# ATtiny44 device description
Architecture: AVR8; Family: tinyAVR
Programming and debug interfaces: ISP, HVSP, debugWIRE
Registers are 8-bit, access not given, no defined reset value unless marked. A register's access mark holds for its fields unless they carry their own. Offsets are from the block's base; lines under a group give offsets from that group; [hi:lo] are bit positions; {n}, {i} and the like mark numbered series; 'fields as' and 'values as' point back to an identical list; <NAME> marks a mode.

## Ordering variants
ATtiny44V-10SSU, ATtiny44V-10SSUR: SOIC14, up to 10 MHz, -40 to 85 C, 1.8 to 5.5 V
ATtiny44V-10MU, ATtiny44V-10MUR: QFN20, up to 10 MHz, -40 to 85 C, 1.8 to 5.5 V
ATtiny44-20SSU, ATtiny44-20SSUR: SOIC14, up to 20 MHz, -40 to 85 C, 2.7 to 5.5 V
ATtiny44-20MU, ATtiny44-20MUR: QFN20, up to 20 MHz, -40 to 85 C, 2.7 to 5.5 V
ATtiny44-15SSZ: SOIC14, up to 16 MHz, -40 to 125 C, 2.7 to 5.5 V
ATtiny44-15MZ: QFN20, up to 16 MHz, -40 to 125 C, 2.7 to 5.5 V

## Memory
prog space: start 0x0000 size 0x1000, little endian
  0x0000 FLASH size 0x1000 flash, rw, executable, page 0x40
signatures space: start 0 size 3, little endian
  0 SIGNATURES size 3 signatures, ro
fuses space: start 0 size 0x0003, little endian
  0 FUSES size 0x0003 fuses, rw
lockbits space: start 0 size 0x0001, little endian
  0 LOCKBITS size 0x0001 lockbits, rw
data space: start 0x0000 size 0x0160, little endian
  0x0000 REGISTERS size 0x0020 regs
  0x0020 MAPPED_IO size 0x0040 io
  0x0060 IRAM size 0x0100 ram
eeprom space: start 0x0000 size 0x0100, little endian
  0x0000 EEPROM size 0x0100 eeprom, rw, page 0x04
io space: start 0x00 size 0x40, little endian
osccal space: start 0 size 1, little endian
  0 OSCCAL size 1 osccal, ro

## Peripheral instances (address, pins/pin function, parameters)
PORTA at 0x00 — I/O Port
PORTB at 0x00 — I/O Port
AC at 0x00 — Analog Comparator
ADC at 0x00 — Analog-to-Digital Converter
USI at 0x00 — Universal Serial Interface
EXINT at 0x00 — External Interrupts
EEPROM at 0x00
WDT at 0x00 — Watchdog Timer
TC0 at 0x00 — Timer/Counter, 8-bit
TC1 at 0x00 — Timer/Counter, 16-bit
BOOT_LOAD at 0x00 — Bootloader
CPU at 0x00 — CPU Registers
  parameters: CORE_VERSION=V2, NEW_INSTRUCTIONS=lpm rd,z+
FUSE at 0 in fuses — Fuses
LOCKBIT at 0 in lockbits — Lockbits

## Interrupts
0 RESET — External Pin, Power-on Reset, Brown-out Reset,Watchdog Reset
1 EXT_INT0 — External Interrupt Request 0
2 PCINT0 — Pin Change Interrupt Request 0
3 PCINT1 — Pin Change Interrupt Request 1
4 WDT — Watchdog Time-out
5 TIM1_CAPT — Timer/Counter1 Capture Event
6 TIM1_COMPA — Timer/Counter1 Compare Match A
7 TIM1_COMPB — Timer/Counter1 Compare Match B
8 TIM1_OVF — Timer/Counter1 Overflow
9 TIM0_COMPA — Timer/Counter0 Compare Match A
10 TIM0_COMPB — Timer/Counter0 Compare Match B
11 TIM0_OVF — Timer/Counter0 Overflow
12 ANA_COMP — Analog Comparator
13 ADC — ADC Conversion Complete
14 EE_RDY — EEPROM Ready
15 USI_STR — USI START
16 USI_OVF — USI Overflow

## Properties
SIGNATURES: JTAGID=0x9207, SIGNATURE0=0x1e, SIGNATURE1=0x92, SIGNATURE2=0x07
OCD: OCD_REVISION=1, OCD_DATAREG=0x27, PROGBASE=0x0000

## LOCKBIT — Lockbits
Instances: LOCKBIT 0 in lockbits
0x00 LOCKBIT reset 0xFF
  [1:0] LB — Memory Lock
    0=PROG_VER_DISABLED (Further programming and verification disabled); 2=PROG_DISABLED (Further programming disabled); 3=NO_LOCK (No memory lock features enabled)

## PORTA — I/O Port
Instances: PORTA 0x00
0x39 PINA — Port A Input Pins
0x3A DDRA — Port A Data Direction Register
0x3B PORTA — Port A Data Register

## PORTB — I/O Port
Instances: PORTB 0x00
0x36 PINB bits used 3:0 — Input Pins, Port B
0x37 DDRB bits used 3:0 — Data Direction Register, Port B
0x38 PORTB bits used 3:0 — Data Register, Port B

## AC — Analog Comparator
Instances: AC 0x00
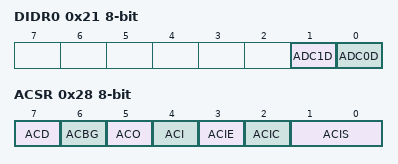
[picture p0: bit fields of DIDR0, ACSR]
0x21 DIDR0
  [1] ADC1D — ADC 1 Digital input buffer disable
  [0] ADC0D — ADC 0 Digital input buffer disable
0x23 ADCSRB — ADC Control and Status Register B
  [6] ACME — Analog Comparator Multiplexer Enable
0x28 ACSR — Analog Comparator Control And Status Register
  [7] ACD — Analog Comparator Disable
  [6] ACBG — Analog Comparator Bandgap Select
  [5] ACO — Analog Compare Output
  [4] ACI — Analog Comparator Interrupt Flag
  [3] ACIE — Analog Comparator Interrupt Enable
  [2] ACIC — Analog Comparator Input Capture Enable
  [1:0] ACIS — Analog Comparator Interrupt Mode Select bits
    0=INTERRUPT_ON_TOGGLE; 2=INTERRUPT_ON_FALLING_EDGE; 3=INTERRUPT_ON_RISING_EDGE
